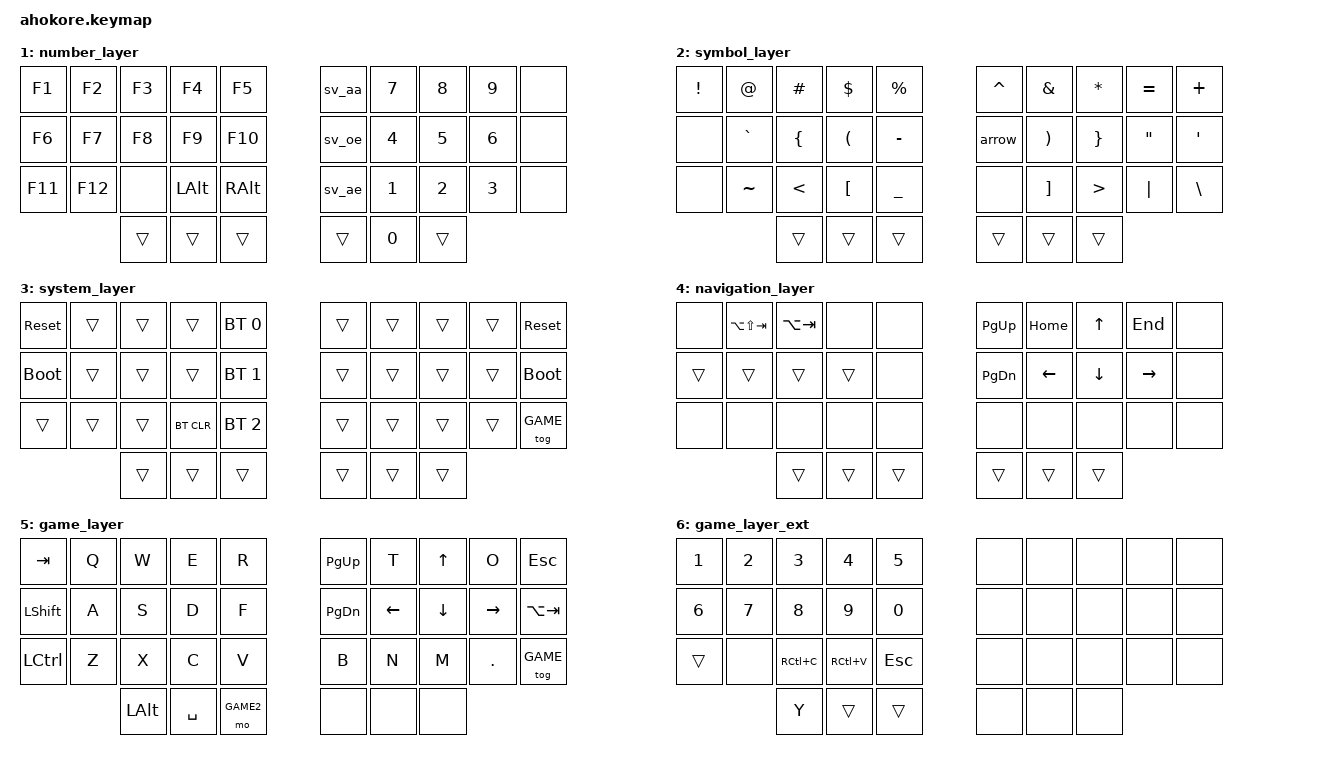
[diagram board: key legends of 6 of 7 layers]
/*
 * Copyright (c) 2020 The ZMK Contributors
 *
 * SPDX-License-Identifier: MIT
 */

#include <behaviors.dtsi>
#include <dt-bindings/zmk/keys.h>
#include <dt-bindings/zmk/bt.h>

// Layer names
#define DEFAULT 0
#define NUM 1
#define SYM 2
#define SYS 3
#define NAV 4
#define GAME 5
#define GAME2 6

// Home row mods macroo
#define HRML(k1,k2,k3,k4) &lhm LSHFT k1  &lhm LCTRL k2  &lhm LWIN k3  &lhm LALT k4
#define HRMR(k1,k2,k3,k4) &rhm LALT k1  &rhm RWIN k2  &rhm RCTRL k3  &rhm RSHFT k4

#define COMBO(NAME, BINDINGS, KEYPOS) \
    combo_##NAME { \
        timeout-ms = <40>; \
        bindings = <BINDINGS>; \
        key-positions = <KEYPOS>; \
	    layers = <DEFAULT NAV>; \
    }

/*
 0  1  2  3  4     5  6  7  8  9
10 11 12 13 14    15 16 17 18 19
20 21 22 23 24    25 26 27 28 29
      30 31 32    33 34 35
*/

/ {
    behaviors {
        ht: hold_tap {
            label = "hold_tap";
            compatible = "zmk,behavior-hold-tap";
            #binding-cells = <2>;
            flavor = "tap-preferred";
            tapping-term-ms = <250>;
            quick-tap-ms = <150>;
            retro-tap;
            bindings = <&kp>, <&kp>;
        };

        lhm: left_homerow_mods {
            compatible = "zmk,behavior-hold-tap";
            label = "LEFT_HOMEROW_MODS";
            #binding-cells = <2>;
            flavor = "balanced";
            tapping-term-ms = <250>;
            require-prior-idle-ms = <150>;
            hold-trigger-on-release;
            bindings = <&kp>, <&kp>;
            hold-trigger-key-positions = <5>, <6>, <7>, <8>, <9>, <15>, <16>, <17>, <18>, <19>, <25>, <26>, <27>, <28>, <29>, <33>, <34>, <35>;
        };

        rhm: right_homerow_mods {
            compatible = "zmk,behavior-hold-tap";
            label = "RIGHT_HOMEROW_MODS";
            #binding-cells = <2>;
            flavor = "balanced";
            tapping-term-ms = <250>;
            require-prior-idle-ms = <150>;
            hold-trigger-on-release;
            bindings = <&kp>, <&kp>;
            hold-trigger-key-positions = <0>, <1>, <2>, <3>, <4>, <10>, <11>, <12>, <13>, <14>, <20>, <21>, <22>, <23>, <24>, <30>, <31>, <32>;
        };

        skq: sticky_key_quick_release {
            compatible = "zmk,behavior-sticky-key";
            label = "STICKY_KEY_QUICK_RELEASE";
            #binding-cells = <1>;
            bindings = <&kp>;
            release-after-ms = <2000>;
            quick-release;
        };

        sv_aa: Swedish_aa {
            compatible = "zmk,behavior-mod-morph";
            label = "SWEDISH_AA";
            #binding-cells = <0>;
            bindings = <&sv_aa_L>, <&sv_aa_U>;
            mods = <(MOD_LSFT|MOD_RSFT)>;
        };
        sv_ae: Swedish_ae {
            compatible = "zmk,behavior-mod-morph";
            label = "SWEDISH_AE";
            #binding-cells = <0>;
            bindings = <&sv_ae_L>, <&sv_ae_U>;
            mods = <(MOD_LSFT|MOD_RSFT)>;
        };
        sv_oe: Swedish_oe {
            compatible = "zmk,behavior-mod-morph";
            label = "SWEDISH_OE";
            #binding-cells = <0>;
            bindings = <&sv_oe_L>, <&sv_oe_U>;
            mods = <(MOD_LSFT|MOD_RSFT)>;
        };
    };

    conditional_layers {
        compatible = "zmk,conditional-layers";
        tri_layer {
            if-layers = <NUM SYM>;
            then-layer = <SYS>;
        };
    };

    combos {
        compatible = "zmk,combos";

        COMBO(esc, &kp ESC, 1 2);
        COMBO(tab, &kp TAB, 11 12);
        COMBO(del, &kp DEL, 6 7);
        COMBO(bksp, &kp BSPC, 7 8);
        COMBO(ent, &kp ENTER, 17 18);
	    COMBO(s_sft, &skq LSHIFT, 26 27);
	    COMBO(capw, &caps_word, 22 23);
    };

    macros {
        /* Swedish ALT codes:
            å: Alt + 134
            Å: Alt + 143
            ä: Alt + 132
            Ä: Alt + 142
            ö: Alt + 148
            Ö: Alt + 153
        */
        sv_aa_L: sv_aa_L {
            label = "MACRO_sv_lower_aa";
            compatible = "zmk,behavior-macro";
            #binding-cells = <0>;
            bindings
                = <&macro_press &kp LALT>
                , <&macro_tap &kp KP_N1 &kp KP_N3 &kp KP_N4>
                , <&macro_release &kp LALT>;
        };
        sv_aa_U: sv_aa_U {
            label = "MACRO_sv_upper_aa";
            compatible = "zmk,behavior-macro";
            #binding-cells = <0>;
            bindings
                = <&macro_press &kp LALT>
                , <&macro_tap &kp KP_N1 &kp KP_N4 &kp KP_N3>
                , <&macro_release &kp LALT>;
        };
        sv_ae_L: sv_ae_L {
            label = "MACRO_sv_lower_ae";
            compatible = "zmk,behavior-macro";
            #binding-cells = <0>;
            bindings
                = <&macro_press &kp LALT>
                , <&macro_tap &kp KP_N1 &kp KP_N3 &kp KP_N2>
                , <&macro_release &kp LALT>;
        };
        sv_ae_U: sv_ae_U {
            label = "MACRO_sv_upper_ae";
            compatible = "zmk,behavior-macro";
            #binding-cells = <0>;
            bindings
                = <&macro_press &kp LALT>
                , <&macro_tap &kp KP_N1 &kp KP_N4 &kp KP_N2>
                , <&macro_release &kp LALT>;
        };
        sv_oe_L: sv_oe_L {
            label = "MACRO_sv_lower_oe";
            compatible = "zmk,behavior-macro";
            #binding-cells = <0>;
            bindings
                = <&macro_press &kp LALT>
                , <&macro_tap &kp KP_N1 &kp KP_N4 &kp KP_N8>
                , <&macro_release &kp LALT>;
        };
        sv_oe_U: sv_oe_U {
            label = "MACRO_sv_upper_oe";
            compatible = "zmk,behavior-macro";
            #binding-cells = <0>;
            bindings
                = <&macro_press &kp LALT>
                , <&macro_tap &kp KP_N1 &kp KP_N5 &kp KP_N3>
                , <&macro_release &kp LALT>;
        };
        arrow: arrow {
            label = "MACRO_cpp_arrow";
            compatible = "zmk,behavior-macro";
            #binding-cells = <0>;
            bindings
                = <&macro_tap &kp MINUS &kp GT>;
        };
    };

    keymap {
        compatible = "zmk,keymap";

        default_layer {
            bindings = <
     &kp Q &kp W &kp E &kp R  &kp T   &kp Y  &kp U &kp I    &kp O   &kp P
    HRML(A,    S,    D,    F) &kp G   &kp H HRMR(J,    K,       L,      SCLN)
     &kp Z &kp X &kp C &kp V  &kp B   &kp N  &kp M &kp CMMA &kp DOT &kp FSLH
             &trans &mo NAV &mo NUM   &mo SYM &kp SPC &trans
            >;
        };
        
        number_layer {
            bindings = <
    &kp F1  &kp F2  &kp F3 &kp F4  &kp F5      &sv_aa &kp N7 &kp N8 &kp N9 &none
    &kp F6  &kp F7  &kp F8 &kp F9  &kp F10     &sv_oe &kp N4 &kp N5 &kp N6 &none
    &kp F11 &kp F12 &none  &kp LALT &kp RALT   &sv_ae &kp N1 &kp N2 &kp N3 &none
                        &trans &trans &trans   &trans &kp N0 &trans
            >;
        };

        symbol_layer {
            bindings = <
    &kp EXCL &kp AT    &kp HASH &kp DLLR   &kp PRCNT &kp CARET &kp AMPS &kp STAR &kp EQUAL &kp PLUS
    &none    &kp GRAVE &kp LBRC &kp LPAR   &kp MINUS &arrow    &kp RPAR &kp RBRC &kp DQT   &kp SQT
    &none    &kp TILDE &kp LT   &kp LBKT   &kp UNDER &none     &kp RBKT &kp GT   &kp PIPE  &kp BSLH
                    &trans &trans &trans   &trans &trans &trans
            >;
        };

        system_layer {
            bindings = <
    &sys_reset  &trans &trans &trans     &bt BT_SEL 0   &trans &trans &trans &trans &sys_reset
    &bootloader &trans &trans &trans     &bt BT_SEL 1   &trans &trans &trans &trans &bootloader
    &trans      &trans &trans &bt BT_CLR &bt BT_SEL 2   &trans &trans &trans &trans &tog GAME
                                 &trans &trans &trans   &trans &trans &trans
            >;
        };

        navigation_layer {
            bindings = <
    &none  &kp LA(LS(TAB)) &kp LA(TAB) &none  &none   &kp PG_UP &kp HOME &kp UP   &kp END   &none
    &trans &trans          &trans      &trans &none   &kp PG_DN &kp LEFT &kp DOWN &kp RIGHT &none
    &none  &none           &none       &none  &none   &none     &none    &none    &none     &none
                               &trans &trans &trans   &trans &trans &trans
            >;
        };

        game_layer {
            bindings = <
    &kp TAB    &kp Q &kp W &kp E &kp R   &kp PG_UP &kp T    &kp UP   &kp O     &kp ESC
    &kp LSHIFT &kp A &kp S &kp D &kp F   &kp PG_DN &kp LEFT &kp DOWN &kp RIGHT &kp LA(TAB)
    &kp LCTRL  &kp Z &kp X &kp C &kp V   &kp B     &kp N    &kp M    &kp DOT   &tog GAME
            &kp LALT &kp SPC &mo GAME2   &none &none &none
            >;
        };

        game_layer_ext {
            bindings = <
    &kp N1 &kp N2 &kp N3    &kp N4    &kp N5    &none &none &none &none &none
    &kp N6 &kp N7 &kp N8    &kp N9    &kp N0    &none &none &none &none &none
    &trans &none  &kp RC(C) &kp RC(V) &kp ESC   &none &none &none &none &none
                          &kp Y &trans &trans   &none &none &none
            >;
        };

    };
};
